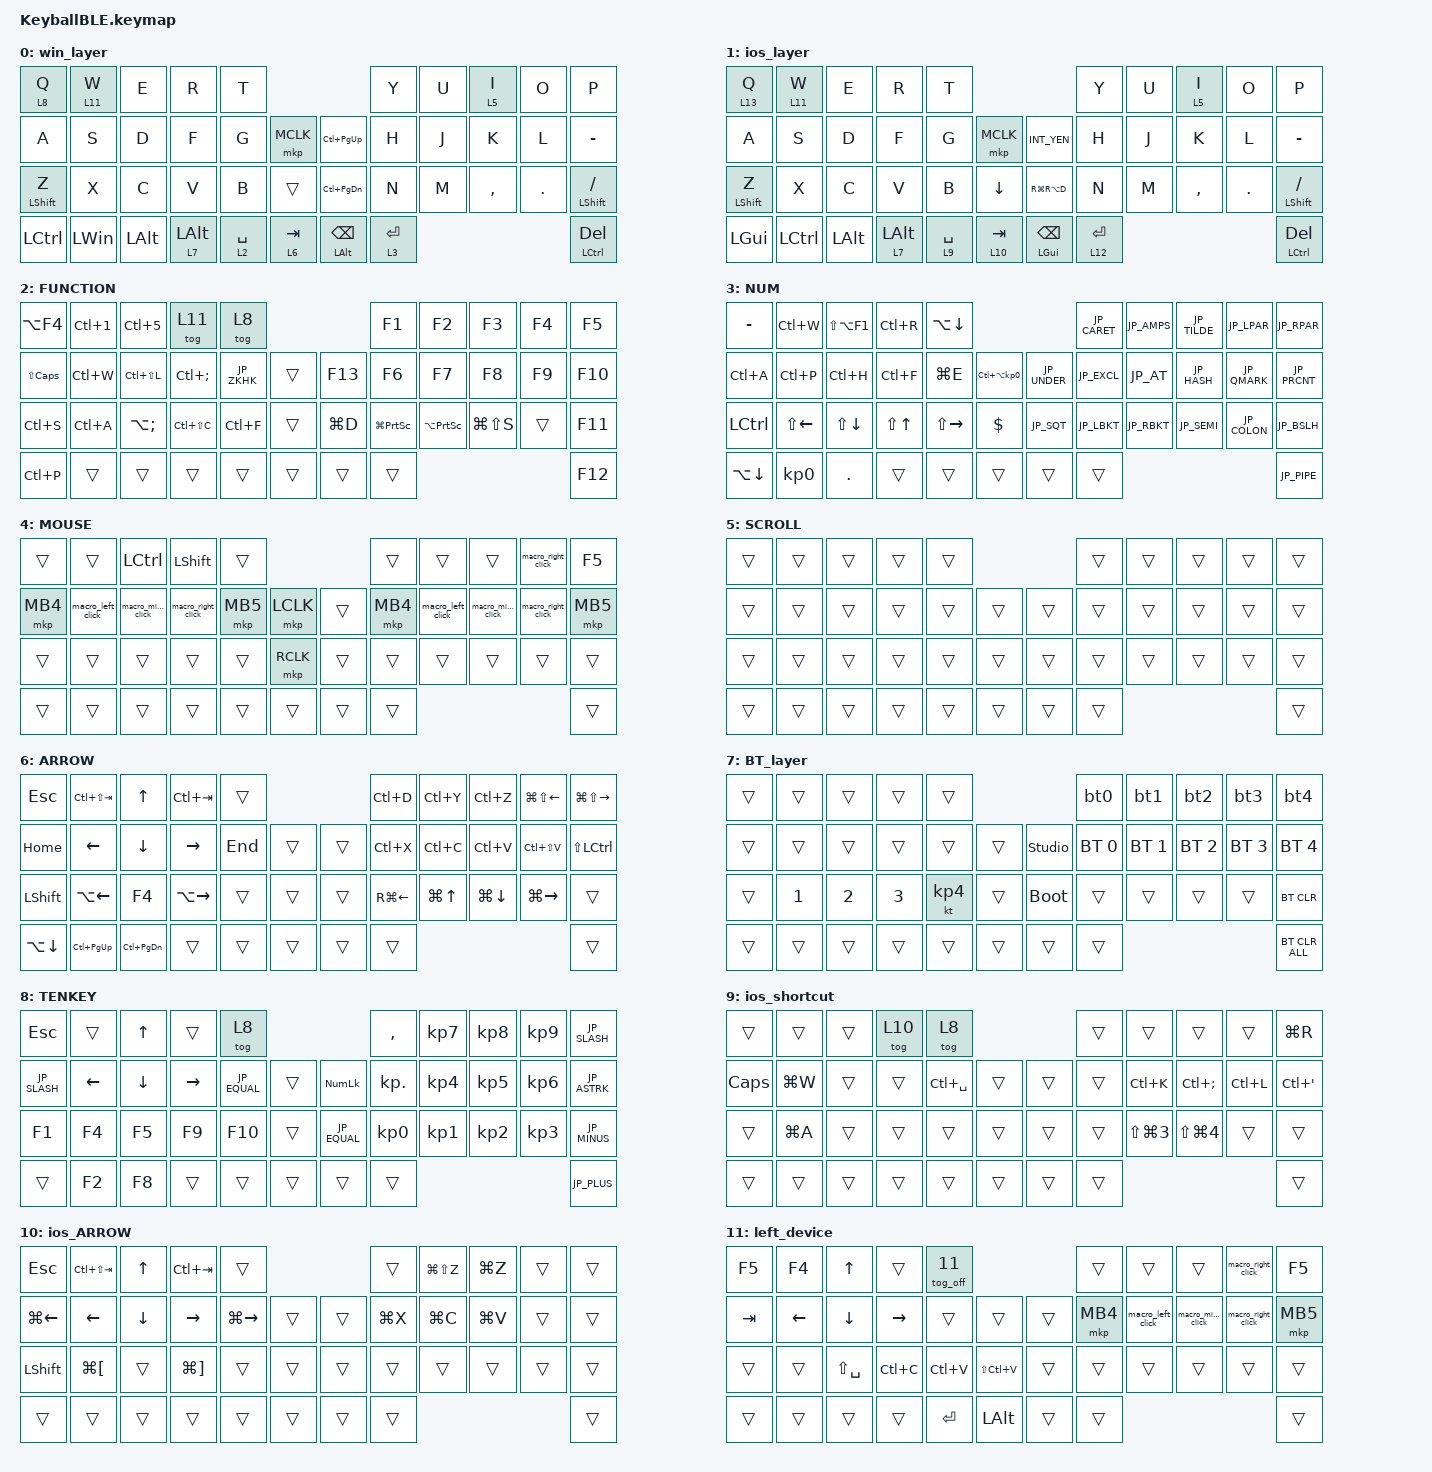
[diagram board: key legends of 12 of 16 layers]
#define ZMK_POINTING_DEFAULT_SCRL_VAL 120    // default: 10

//#include <layout_shift.dtsi>

#include <layout_shift_kp_override.dtsi>
#include "keycode_japanese.h"
#include <behaviors.dtsi>
#include <dt-bindings/zmk/bt.h>
#include <dt-bindings/zmk/keys.h>
#include <dt-bindings/zmk/pointing.h>

#define MOUSE 4
#define SCROLL 5
#define NUM 3

/ {
    layout_shift {
        compatible = "zmk,layout-shift";
        status = "okay";
    };
};

&mt {
    flavor = "balanced";
    quick-tap-ms = <300>;
};

&sl { release-after-ms = <180>; };

/ {
    combos {
        compatible = "zmk,combos";

        double_quotation {
            bindings = <&kp JP_DQT>;
            key-positions = <20 21>;
        };

        EQ {
            bindings = <&kp JP_EQUAL>;
            key-positions = <8 9>;
            layers = <8>;
            require-prior-idle-ms = <400>;
        };

        Escape {
            bindings = <&kp ESC>;
            key-positions = <0 1>;
            layers = <0 1>;
            require-prior-idle-ms = <400>;
        };

        cap_word {
            bindings = <&caps_word>;
            key-positions = <22 33>;
            layers = <0 1>;
            require-prior-idle-ms = <400>;
        };

        Ctrl_A {
            bindings = <&kp LC(A)>;
            key-positions = <10 11>;
            layers = <0 1 4>;
            require-prior-idle-ms = <400>;
        };

        Ctrl_W {
            bindings = <&kp LC(W)>;
            key-positions = <1 2>;
            layers = <0 1 4>;
            require-prior-idle-ms = <400>;
        };

        Ctrl_R {
            bindings = <&kp LC(R)>;
            key-positions = <2 3>;
            layers = <0 1 4>;
            require-prior-idle-ms = <400>;
        };

        Ctrl_T {
            bindings = <&kp LC(T)>;
            key-positions = <3 4>;
            require-prior-idle-ms = <400>;
            layers = <0 1 4>;
        };

        Ctrl_Z {
            bindings = <&kp LC(Z)>;
            key-positions = <23 22>;
            require-prior-idle-ms = <400>;
            layers = <0 1 4>;
        };

        Ctrl_X {
            bindings = <&kp LC(X)>;
            key-positions = <23 24>;
            require-prior-idle-ms = <400>;
            layers = <0 1 4>;
        };

        Ctrl_C {
            bindings = <&kp LC(C)>;
            key-positions = <24 25>;
            require-prior-idle-ms = <400>;
            layers = <0 1 4>;
        };

        Ctrl_V {
            bindings = <&kp LC(V)>;
            key-positions = <26 25>;
            require-prior-idle-ms = <400>;
            layers = <0 1 4>;
        };

        Ctrl_N {
            bindings = <&kp LC(N)>;
            key-positions = <29 30>;
            require-prior-idle-ms = <400>;
            layers = <0 1 4>;
        };

        Ctrl_S {
            bindings = <&kp LC(S)>;
            key-positions = <11 12>;
            require-prior-idle-ms = <400>;
            layers = <0 1 4>;
        };

        Ctrl_F {
            bindings = <&kp LC(F)>;
            key-positions = <13 14>;
            require-prior-idle-ms = <400>;
            layers = <0 1 4>;
        };

        Ctrl_H {
            bindings = <&kp LC(H)>;
            key-positions = <17 18>;
            require-prior-idle-ms = <400>;
            layers = <0 1 4>;
        };

        Ctrl_P {
            bindings = <&kp LC(P)>;
            key-positions = <8 9>;
            require-prior-idle-ms = <400>;
            layers = <0 1 4>;
        };

        Ctrl_SHIFT_V {
            bindings = <&kp LC(LS(V))>;
            key-positions = <26 27>;
            require-prior-idle-ms = <400>;
            layers = <0 1 4>;
        };

        Ctrl_D {
            bindings = <&kp LC(D)>;
            key-positions = <12 13>;
            require-prior-idle-ms = <400>;
            layers = <0 1 4>;
        };

        Ctrl_Y {
            bindings = <&kp LC(Y)>;
            key-positions = <5 6>;
            require-prior-idle-ms = <400>;
            layers = <0 1 4>;
        };
    };

    macros {
        to_layer_0: to_layer_0 {
            compatible = "zmk,behavior-macro-one-param";
            #binding-cells = <1>;
            bindings = <&to 0 &macro_param_1to1 &kp MACRO_PLACEHOLDER>;
            label = "TO_LAYER_0";
        };

        macro_left_click: macro_left_click {
            compatible = "zmk,behavior-macro";
            #binding-cells = <0>;
            bindings =
                <&macro_press>,
                <&mkp LCLK>,
                <&macro_pause_for_release>,
                <&macro_release>,
                <&mkp LCLK>,
                <&macro_tap>,
                <&tog_off 4 &sl 4>;

            label = "MACRO_LEFT_CLICK";
        };

        bt0: bt0 {
            compatible = "zmk,behavior-macro";
            #binding-cells = <0>;
            bindings =
                <&tog_off 1>,
                <&macro_wait_time 200>,
                <&bt BT_SEL 0>,
                <&macro_wait_time 500>,
                <&tog_on 1>;

            label = "BT0";
        };

        bt1: bt1 {
            compatible = "zmk,behavior-macro";
            #binding-cells = <0>;
            bindings =
                <&tog_off 1>,
                <&macro_wait_time 200>,
                <&bt BT_SEL 1>,
                <&macro_wait_time 500>,
                <&tog_on 1>;

            label = "BT1";
        };

        bt2: bt2 {
            compatible = "zmk,behavior-macro";
            #binding-cells = <0>;
            bindings =
                <&tog_off 1>,
                <&macro_wait_time 200>,
                <&bt BT_SEL 2>,
                <&macro_wait_time 500>;

            label = "BT2";
        };

        bt3: bt3 {
            compatible = "zmk,behavior-macro";
            #binding-cells = <0>;
            bindings =
                <&tog_off 1>,
                <&macro_wait_time 200>,
                <&bt BT_SEL 3>,
                <&macro_wait_time 500>,
                <&tog_on 1>;

            label = "BT3";
        };

        bt4: bt4 {
            compatible = "zmk,behavior-macro";
            #binding-cells = <0>;
            bindings =
                <&tog_off 1>,
                <&macro_wait_time 200>,
                <&bt BT_SEL 4>,
                <&macro_wait_time 500>;

            label = "BT4";
        };

        to_layer_1: to_layer_1 {
            compatible = "zmk,behavior-macro-one-param";
            #binding-cells = <1>;
            bindings = <&to 1 &macro_param_1to1 &kp MACRO_PLACEHOLDER>;
            label = "TO_LAYER_1";
        };

        macro_right_click: macro_right_click {
            compatible = "zmk,behavior-macro";
            #binding-cells = <0>;
            bindings =
                <&macro_press>,
                <&mkp RCLK>,
                <&macro_pause_for_release>,
                <&macro_release>,
                <&mkp RCLK>,
                <&macro_tap>,
                <&tog_off 4 &sl 4>;

            label = "MACRO_RIGHT_CLICK";
        };

        macro_middle_click: macro_middle_click {
            compatible = "zmk,behavior-macro";
            #binding-cells = <0>;
            bindings =
                <&macro_press>,
                <&mkp MCLK>,
                <&macro_pause_for_release>,
                <&macro_release>,
                <&mkp MCLK>,
                <&macro_tap>,
                <&tog_off 4 &sl 4>;

            label = "MACRO_MIDDLE_CLICK";
        };

        kp_to: kp_to {
            compatible = "zmk,behavior-macro-two-param";
            wait-ms = <0>;
            tap-ms = <0>;
            #binding-cells = <2>;
            bindings = <&macro_param_1to1 &kp MACRO_PLACEHOLDER &macro_param_2to1 &to MACRO_PLACEHOLDER>;
        };
    };

    behaviors {
        lt_to_layer_0: lt_to_layer_0 {
            compatible = "zmk,behavior-hold-tap";
            label = "LAYER_TAP_TO_0";
            bindings = <&mo>, <&to_layer_0>;

            #binding-cells = <2>;
            tapping-term-ms = <200>;
        };

        ROTATE: ROTATE {
            compatible = "zmk,behavior-sensor-rotate-var";
            label = "ROTATE";
            #sensor-binding-cells = <2>;
            bindings = <&msc>, <&msc>;

            tap-ms = <20>;
        };

        tog_on: toggle_layer_on_only {
            compatible = "zmk,behavior-toggle-layer";
            #binding-cells = <1>;
            display-name = "Toggle Layer On";
            toggle-mode = "on";
        };

        tog_off: toggle_layer_off_only {
            compatible = "zmk,behavior-toggle-layer";
            #binding-cells = <1>;
            display-name = "Toggle Layer Off";
            toggle-mode = "off";
        };

        lt_to_layer_1: lt_to_layer_1 {
            compatible = "zmk,behavior-hold-tap";
            label = "LT_TO_LAYER_1";
            bindings = <&mo>, <&to_layer_1>;

            #binding-cells = <2>;
            tapping-term-ms = <200>;
        };

        kt_on: key_toggle_on_only {
            compatible = "zmk,behavior-key-toggle";
            #binding-cells = <1>;
            display-name = "Key Toggle On";
            toggle-mode = "on";
        };

        /omit-if-no-ref/

        kt_off: key_toggle_off_only {
            compatible = "zmk,behavior-key-toggle";
            #binding-cells = <1>;
            display-name = "Key Toggle Off";
            toggle-mode = "off";
        };

        alt_tab: alt_tab {
            compatible = "zmk,behavior-macro-two-param";
            #binding-cells = <2>;
            bindings = <&macro_param_1to1 &kt_on MACRO_PLACEHOLDER &macro_param_2to1 &kp MACRO_PLACEHOLDER &macro_param_1to1 &sk MACRO_PLACEHOLDER &macro_param_1to1 &kt_off MACRO_PLACEHOLDER>;
        };
    };

    keymap {
        compatible = "zmk,keymap";

        win_layer {
            bindings = <
&lt 8 Q           &lt 11 W      &kp E         &kp R                      &kp T                                                          &kp Y        &kp U  &lt 5 I    &kp O       &kp P
&kp A             &kp S         &kp D         &kp F                      &kp G        &mkp MCLK                 &kp LC(PAGE_UP)         &kp H        &kp J  &kp K      &kp L       &kp MINUS
&mt LEFT_SHIFT Z  &kp X         &kp C         &kp V                      &kp B        &trans                    &kp LC(PAGE_DOWN)       &kp N        &kp M  &kp COMMA  &kp PERIOD  &mt LEFT_SHIFT SLASH
&kp LCTRL         &kp LEFT_WIN  &kp LEFT_ALT  &lt_to_layer_0 7 LEFT_ALT  &lt 2 SPACE  &lt_to_layer_0 6 TAB      &mt LEFT_ALT BACKSPACE  &lt 3 ENTER                                &mt LEFT_CONTROL DEL
            >;

            sensor-bindings = <&ROTATE SCRL_DOWN SCRL_UP>;
        };

        ios_layer {
            bindings = <
&lt 13 Q          &lt 11 W          &kp E         &kp R                      &kp T                                                           &kp Y         &kp U  &lt 5 I    &kp O       &kp P
&kp A             &kp S             &kp D         &kp F                      &kp G        &mkp MCLK                  &kp INT_YEN             &kp H         &kp J  &kp K      &kp L       &kp MINUS
&mt LEFT_SHIFT Z  &kp X             &kp C         &kp V                      &kp B        &kp DOWN_ARROW             &kp RG(RA(D))           &kp N         &kp M  &kp COMMA  &kp PERIOD  &mt LEFT_SHIFT SLASH
&kp LEFT_GUI      &kp LEFT_CONTROL  &kp LEFT_ALT  &lt_to_layer_1 7 LEFT_ALT  &lt 9 SPACE  &lt_to_layer_1 10 TAB      &mt LEFT_GUI BACKSPACE  &lt 12 ENTER                                &mt LEFT_CONTROL DEL
            >;

            sensor-bindings = <&ROTATE SCRL_DOWN SCRL_UP>;
        };

        FUNCTION {
            bindings = <
&kp LA(F4)    &kp LC(NUMBER_1)  &kp LC(N5)         &tog 11            &tog 8                              &kp F1               &kp F2               &kp F3         &kp F4  &kp F5
&kp LS(CAPS)  &kp LC(W)         &kp LC(LS(L))      &kp LC(SEMICOLON)  &kp JP_ZKHK  &trans      &kp F13    &kp F6               &kp F7               &kp F8         &kp F9  &kp F10
&kp LC(S)     &kp LC(A)         &kp LA(SEMICOLON)  &kp LC(LS(C))      &kp LC(F)    &trans      &kp LG(D)  &kp LG(PRINTSCREEN)  &kp LA(PRINTSCREEN)  &kp LG(LS(S))  &trans  &kp F11
&kp LC(P)     &trans            &trans             &trans             &trans       &trans      &trans     &trans                                                           &kp F12
            >;

            sensor-bindings = <&inc_dec_kp C_VOLUME_DOWN C_VOLUME_UP>;
        };

        NUM {
            bindings = <
&kp MINUS     &kp LC(W)        &kp LS(LA(F1))  &kp LC(R)         &kp LA(DOWN)                                              &kp JP_CARET  &kp JP_AMPS  &kp JP_TILDE  &kp JP_LPAR   &kp JP_RPAR
&kp LC(A)     &kp LC(P)        &kp LC(H)       &kp LC(F)         &kp LG(E)      &kp LC(LA(KP_NUMBER_0))      &kp JP_UNDER  &kp JP_EXCL   &kp JP_AT    &kp JP_HASH   &kp JP_QMARK  &kp JP_PRCNT
&kp LCTRL     &kp LS(LEFT)     &kp LS(DOWN)    &kp LS(UP_ARROW)  &kp LS(RIGHT)  &kp DOLLAR                   &kp JP_SQT    &kp JP_LBKT   &kp JP_RBKT  &kp JP_SEMI   &kp JP_COLON  &kp JP_BSLH
&kp LA(DOWN)  &kp KP_NUMBER_0  &kp PERIOD      &trans            &trans         &trans                       &trans        &trans                                                 &kp JP_PIPE
            >;
        };

        MOUSE {
            bindings = <
&trans    &trans             &kp LCTRL            &kp LEFT_SHIFT      &trans                           &trans    &trans             &trans               &macro_right_click  &kp F5
&mkp MB4  &macro_left_click  &macro_middle_click  &macro_right_click  &mkp MB5  &mkp LCLK      &trans  &mkp MB4  &macro_left_click  &macro_middle_click  &macro_right_click  &mkp MB5
&trans    &trans             &trans               &trans              &trans    &mkp RCLK      &trans  &trans    &trans             &trans               &trans              &trans
&trans    &trans             &trans               &trans              &trans    &trans         &trans  &trans                                                                &trans
            >;
        };

        SCROLL {
            bindings = <
&trans  &trans  &trans  &trans  &trans                      &trans  &trans  &trans  &trans  &trans
&trans  &trans  &trans  &trans  &trans  &trans      &trans  &trans  &trans  &trans  &trans  &trans
&trans  &trans  &trans  &trans  &trans  &trans      &trans  &trans  &trans  &trans  &trans  &trans
&trans  &trans  &trans  &trans  &trans  &trans      &trans  &trans                          &trans
            >;
        };

        ARROW {
            bindings = <
&kp ESCAPE          &kp LC(LS(TAB))     &kp UP_ARROW       &kp LC(TAB)          &trans                       &kp LC(D)     &kp LC(Y)         &kp LC(Z)     &kp LG(LS(LEFT))  &kp LG(LS(RIGHT))
&kp HOME            &kp LEFT_ARROW      &kp DOWN_ARROW     &kp RIGHT_ARROW      &kp END  &trans      &trans  &kp LC(X)     &kp LC(C)         &kp LC(V)     &kp LC(LS(V))     &kp LS(LCTRL)
&kp LEFT_SHIFT      &kp LA(LEFT_ARROW)  &kp F4             &kp LA(RIGHT_ARROW)  &trans   &trans      &trans  &kp RG(LEFT)  &kp LG(UP_ARROW)  &kp LG(DOWN)  &kp LG(RIGHT)     &trans
&kp LA(DOWN_ARROW)  &kp LC(PAGE_UP)     &kp LC(PAGE_DOWN)  &trans               &trans   &trans      &trans  &trans                                                          &trans
            >;

            sensor-bindings = <&inc_dec_kp LC(PAGE_UP) LC(PAGE_DOWN)>;
        };

        BT_layer {
            bindings = <
&trans  &trans        &trans        &trans        &trans                                 &bt0          &bt1          &bt2          &bt3          &bt4
&trans  &trans        &trans        &trans        &trans     &trans      &studio_unlock  &bt BT_SEL 0  &bt BT_SEL 1  &bt BT_SEL 2  &bt BT_SEL 3  &bt BT_SEL 4
&trans  &kp NUMBER_1  &kp NUMBER_2  &kp NUMBER_3  &kt KP_N4  &trans      &bootloader     &trans        &trans        &trans        &trans        &bt BT_CLR
&trans  &trans        &trans        &trans        &trans     &trans      &trans          &trans                                                  &bt BT_CLR_ALL
            >;
        };

        TENKEY {
            bindings = <
&kp ESC       &trans    &kp UP_ARROW    &trans     &tog 8                                    &kp COMMA        &kp KP_NUMBER_7  &kp KP_NUMBER_8  &kp KP_NUMBER_9  &kp JP_SLASH
&kp JP_SLASH  &kp LEFT  &kp DOWN_ARROW  &kp RIGHT  &kp JP_EQUAL  &trans      &kp KP_NUMLOCK  &kp KP_DOT       &kp KP_NUMBER_4  &kp KP_NUMBER_5  &kp KP_NUMBER_6  &kp JP_ASTRK
&kp F1        &kp F4    &kp F5          &kp F9     &kp F10       &trans      &kp JP_EQUAL    &kp KP_NUMBER_0  &kp KP_NUMBER_1  &kp KP_NUMBER_2  &kp KP_NUMBER_3  &kp JP_MINUS
&trans        &kp F2    &kp F8          &trans     &trans        &trans      &trans          &trans                                                              &kp JP_PLUS
            >;
        };

        ios_shortcut {
            bindings = <
&trans    &trans     &trans  &tog 10  &tog 8                             &trans  &trans                &trans                &trans     &kp LG(R)
&kp CAPS  &kp LG(W)  &trans  &trans   &kp LC(SPACE)  &trans      &trans  &trans  &kp LC(K)             &kp LC(SEMI)          &kp LC(L)  &kp LC(SQT)
&trans    &kp LG(A)  &trans  &trans   &trans         &trans      &trans  &trans  &kp LS(LG(NUMBER_3))  &kp LS(LG(NUMBER_4))  &trans     &trans
&trans    &trans     &trans  &trans   &trans         &trans      &trans  &trans                                                         &trans
            >;

            sensor-bindings = <&inc_dec_kp C_VOLUME_DOWN C_VOLUME_UP>;
        };

        ios_ARROW {
            bindings = <
&kp ESCAPE          &kp LC(LS(TAB))       &kp UP_ARROW    &kp LC(TAB)            &trans                             &trans     &kp LG(LS(Z))  &kp LG(Z)  &trans  &trans
&kp LG(LEFT_ARROW)  &kp LEFT_ARROW        &kp DOWN_ARROW  &kp RIGHT_ARROW        &kp LG(RIGHT)  &trans      &trans  &kp LG(X)  &kp LG(C)      &kp LG(V)  &trans  &trans
&kp LEFT_SHIFT      &kp LG(LEFT_BRACKET)  &trans          &kp LG(RIGHT_BRACKET)  &trans         &trans      &trans  &trans     &trans         &trans     &trans  &trans
&trans              &trans                &trans          &trans                 &trans         &trans      &trans  &trans                                       &trans
            >;

            sensor-bindings = <&inc_dec_kp LC(PAGE_UP) LC(PAGE_DOWN)>;
        };

        left_device {
            bindings = <
&kp F5   &kp F4          &kp UP_ARROW    &trans     &tog_off 11                             &trans    &trans             &trans               &macro_right_click  &kp F5
&kp TAB  &kp LEFT_ARROW  &kp DOWN_ARROW  &kp RIGHT  &trans       &trans             &trans  &mkp MB4  &macro_left_click  &macro_middle_click  &macro_right_click  &mkp MB5
&trans   &trans          &kp LS(SPACE)   &kp LC(C)  &kp LC(V)    &kp LS(LC(V))      &trans  &trans    &trans             &trans               &trans              &trans
&trans   &trans          &trans          &trans     &kp ENTER    &kp LEFT_ALT       &trans  &trans                                                                &trans
            >;
        };

        NUM_ios {
            bindings = <
&kp MINUS     &kp LC(W)        &kp LS(LA(F1))  &kp LC(R)         &kp LA(DOWN)                                                  &kp CARET         &kp AMPERSAND      &kp TILDE  &kp LEFT_PARENTHESIS  &kp RIGHT_PARENTHESIS
&kp LC(A)     &kp LC(P)        &kp LC(H)       &kp LC(F)         &kp LG(E)      &kp LC(LA(KP_NUMBER_0))      &kp UNDERSCORE    &kp EXCLAMATION   &kp AT             &kp HASH   &kp QUESTION          &kp PERCENT
&kp LCTRL     &kp LS(LEFT)     &kp LS(DOWN)    &kp LS(UP_ARROW)  &kp LS(RIGHT)  &kp DOLLAR                   &kp SINGLE_QUOTE  &kp LEFT_BRACKET  &kp RIGHT_BRACKET  &kp SEMI   &kp COLON             &kp BACKSLASH
&kp LA(DOWN)  &kp KP_NUMBER_0  &kp PERIOD      &trans            &trans         &trans                       &trans            &trans                                                                &kp PIPE
            >;
        };

        TENKEY_IOS {
            bindings = <
&kp ESC    &trans    &kp UP_ARROW    &trans     &tog 8                                 &kp COMMA        &kp KP_NUMBER_7  &kp KP_NUMBER_8  &kp KP_NUMBER_9  &kp SLASH
&kp SLASH  &kp LEFT  &kp DOWN_ARROW  &kp RIGHT  &kp EQUAL  &trans      &kp KP_NUMLOCK  &kp KP_DOT       &kp KP_NUMBER_4  &kp KP_NUMBER_5  &kp KP_NUMBER_6  &kp ASTERISK
&kp F1     &kp F4    &kp F5          &kp F9     &kp F10    &trans      &kp EQUAL       &kp KP_NUMBER_0  &kp KP_NUMBER_1  &kp KP_NUMBER_2  &kp KP_NUMBER_3  &kp MINUS
&trans     &kp F2    &kp F8          &trans     &trans     &trans      &trans          &trans                                                              &kp PLUS
            >;
        };

        FUNCTION_IOS {
            bindings = <
&kp LA(F4)    &kp LC(NUMBER_1)  &kp LC(N5)         &tog 11            &tog 8                                &kp F1               &kp F2               &kp F3         &kp F4  &kp F5
&kp LS(CAPS)  &kp LC(W)         &kp LC(LS(L))      &kp LC(SEMICOLON)  &kp LC(SPACE)  &trans      &kp F13    &kp F6               &kp F7               &kp F8         &kp F9  &kp F10
&kp LC(S)     &kp LC(A)         &kp LA(SEMICOLON)  &kp LC(LS(C))      &kp LC(F)      &trans      &kp LG(D)  &kp LG(PRINTSCREEN)  &kp LA(PRINTSCREEN)  &kp LG(LS(S))  &trans  &kp F11
&kp LC(P)     &trans            &trans             &trans             &trans         &trans      &trans     &trans                                                           &kp F12
            >;

            sensor-bindings = <&inc_dec_kp C_VOLUME_DOWN C_VOLUME_UP>;
        };

        MOUSE_TEMP {
            bindings = <
&trans    &trans             &kp LCTRL            &kp LEFT_SHIFT      &trans                           &trans    &trans             &trans               &macro_right_click  &kp F5
&mkp MB4  &macro_left_click  &macro_middle_click  &macro_right_click  &mkp MB5  &mkp LCLK      &trans  &mkp MB4  &macro_left_click  &macro_middle_click  &macro_right_click  &mkp MB5
&trans    &trans             &trans               &trans              &trans    &mkp RCLK      &trans  &trans    &trans             &trans               &trans              &trans
&trans    &trans             &trans               &trans              &trans    &trans         &trans  &trans                                                                &trans
            >;
        };
    };
};
